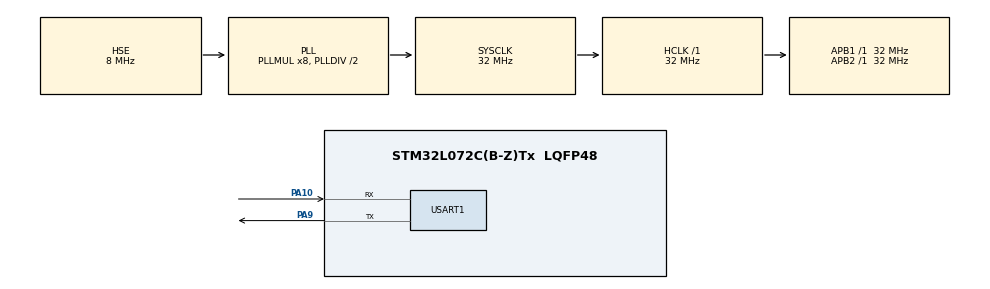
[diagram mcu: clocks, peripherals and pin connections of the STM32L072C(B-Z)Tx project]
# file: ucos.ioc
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Mcu.Family=STM32L0
Mcu.Name=STM32L072C(B-Z)Tx
Mcu.Package=LQFP48
PA10.Mode=Asynchronous
PA10.Signal=USART1_RX
PA13.Mode=Serial_Wire
PA13.Signal=SYS_SWDIO
PA14.Mode=Serial_Wire
PA14.Signal=SYS_SWCLK
PA9.Mode=Asynchronous
PA9.Signal=USART1_TX
PH0-OSC_IN.Mode=HSE-External-Oscillator
PH0-OSC_IN.Signal=RCC_OSC_IN
PH1-OSC_OUT.Mode=HSE-External-Oscillator
PH1-OSC_OUT.Signal=RCC_OSC_OUT
ProjectManager.HeapSize=0x200
ProjectManager.StackSize=0x400
ProjectManager.TargetToolchain=MDK-ARM V5
RCC.AHBFreq_Value=32000000
RCC.APB1Freq_Value=32000000
RCC.APB1TimFreq_Value=32000000
RCC.APB2Freq_Value=32000000
RCC.APB2TimFreq_Value=32000000
RCC.HCLKFreq_Value=32000000
RCC.HSE_VALUE=8000000
RCC.HSI16_VALUE=16000000
RCC.HSI48_VALUE=48000000
RCC.HSI_VALUE=16000000
RCC.LSE_VALUE=32768
RCC.MSI_VALUE=2097000
RCC.PLLMUL=RCC_PLLMUL_8
RCC.PLLSourceVirtual=RCC_PLLSOURCE_HSE
RCC.SYSCLKFreq_VALUE=32000000
RCC.SYSCLKSource=RCC_SYSCLKSOURCE_PLLCLK
RCC.VCOOutputFreq_Value=64000000
USART1.VirtualMode-Asynchronous=VM_ASYNC
USART1.WordLength=WORDLENGTH_8B
board=ucos

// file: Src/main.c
/**
  ******************************************************************************
  * File Name          : main.c
  * Description        : Main program body
  ******************************************************************************
  ** This notice applies to any and all portions of this file
  * that are not between comment pairs USER CODE BEGIN and
  * USER CODE END. Other portions of this file, whether
  * inserted by the user or by software development tools
  * are owned by their respective copyright owners.
  *
  * COPYRIGHT(c) 2018 STMicroelectronics
  *
  * Redistribution and use in source and binary forms, with or without modification,
  * are permitted provided that the following conditions are met:
  *   1. Redistributions of source code must retain the above copyright notice,
  *      this list of conditions and the following disclaimer.
  *   2. Redistributions in binary form must reproduce the above copyright notice,
  *      this list of conditions and the following disclaimer in the documentation
  *      and/or other materials provided with the distribution.
  *   3. Neither the name of STMicroelectronics nor the names of its contributors
  *      may be used to endorse or promote products derived from this software
  *      without specific prior written permission.
  *
  * THIS SOFTWARE IS PROVIDED BY THE COPYRIGHT HOLDERS AND CONTRIBUTORS "AS IS"
  * AND ANY EXPRESS OR IMPLIED WARRANTIES, INCLUDING, BUT NOT LIMITED TO, THE
  * IMPLIED WARRANTIES OF MERCHANTABILITY AND FITNESS FOR A PARTICULAR PURPOSE ARE
  * DISCLAIMED. IN NO EVENT SHALL THE COPYRIGHT HOLDER OR CONTRIBUTORS BE LIABLE
  * FOR ANY DIRECT, INDIRECT, INCIDENTAL, SPECIAL, EXEMPLARY, OR CONSEQUENTIAL
  * DAMAGES (INCLUDING, BUT NOT LIMITED TO, PROCUREMENT OF SUBSTITUTE GOODS OR
  * SERVICES; LOSS OF USE, DATA, OR PROFITS; OR BUSINESS INTERRUPTION) HOWEVER
  * CAUSED AND ON ANY THEORY OF LIABILITY, WHETHER IN CONTRACT, STRICT LIABILITY,
  * OR TORT (INCLUDING NEGLIGENCE OR OTHERWISE) ARISING IN ANY WAY OUT OF THE USE
  * OF THIS SOFTWARE, EVEN IF ADVISED OF THE POSSIBILITY OF SUCH DAMAGE.
  *
  ******************************************************************************
  */

#include "main.h"
#include "stm32l0xx_hal.h"
#include "usart.h"
#include "gpio.h"

/* USER CODE BEGIN Includes */

#include "os.h"

/* USER CODE END Includes */

/* USER CODE BEGIN PV */
/* Private variables ---------------------------------------------------------*/

/* USER CODE END PV */

void SystemClock_Config(void);

/* USER CODE BEGIN PFP */
/* Private function prototypes -----------------------------------------------*/

/* USER CODE END PFP */

/* USER CODE BEGIN 0 */

static  OS_TCB          AppTaskStartTCB;

static  CPU_STK         AppTaskStartStk[APP_CFG_TASK_START_STK_SIZE];

        OS_TMR          AppLED3Tmr;
        OS_SEM          AppLED3Sem;

        OS_TMR          AppLED4Tmr;
        OS_Q            AppLED4MsgQ;

        CPU_INT08U      AppLEDNbr;

/*
*********************************************************************************************************
*                                         FUNCTION PROTOTYPES
*********************************************************************************************************
*/

static  void  AppTaskStart              (void        *p_arg);
                                                                /* Timer callback functions for LED applications        */
        void  AppLED3TmrCallBack        (OS_TMR *p_tmr,
                                         void   *p_arg);

        void  AppLED4TmrCallBack        (OS_TMR *p_tmr,
                                         void   *p_arg);

/* USER CODE END 0 */

int main(void)
{

  /* USER CODE BEGIN 1 */

	OS_ERR      err;
#if (CPU_CFG_NAME_ERR == DEF_ENABLED)
    CPU_ERR     cpu_err;
#endif

  /* USER CODE END 1 */

  /* MCU Configuration----------------------------------------------------------*/

  /* Reset of all peripherals, Initializes the Flash interface and the Systick. */
  HAL_Init();

  /* Configure the system clock */
  SystemClock_Config();

  /* Initialize all configured peripherals */
  MX_GPIO_Init();
  MX_USART1_UART_Init();

  /* USER CODE BEGIN 2 */

	  CPU_Init();

    OSInit(&err);                                               /* Initialize "uC/OS-II, The Real-Time Kernel"          */

    OSTaskCreate((OS_TCB      *)&AppTaskStartTCB,               /* Create the start task                                */
                 (CPU_CHAR    *)"App Task Start",
                 (OS_TASK_PTR  )AppTaskStart,
                 (void        *)0,
                 (OS_PRIO      )APP_CFG_TASK_START_PRIO,
                 (CPU_STK     *)&AppTaskStartStk[0],
                 (CPU_STK_SIZE )APP_CFG_TASK_START_STK_SIZE_LIMIT,
                 (CPU_STK_SIZE )APP_CFG_TASK_START_STK_SIZE,
                 (OS_MSG_QTY   )0,
                 (OS_TICK      )0,
                 (void        *)0,
                 (OS_OPT       )(OS_OPT_TASK_STK_CHK | OS_OPT_TASK_STK_CLR),
                 (OS_ERR      *)&err);

    OSStart(&err);                                              /* Start multitasking (i.e. give control to uC/OS-II)   */

    return (1);
}

/** System Clock Configuration
*/
void SystemClock_Config(void)
{

  RCC_OscInitTypeDef RCC_OscInitStruct;
  RCC_ClkInitTypeDef RCC_ClkInitStruct;
  RCC_PeriphCLKInitTypeDef PeriphClkInit;

    /**Configure the main internal regulator output voltage
    */
  __HAL_PWR_VOLTAGESCALING_CONFIG(PWR_REGULATOR_VOLTAGE_SCALE1);

    /**Initializes the CPU, AHB and APB busses clocks
    */
  RCC_OscInitStruct.OscillatorType = RCC_OSCILLATORTYPE_HSE;
  RCC_OscInitStruct.HSEState = RCC_HSE_ON;
  RCC_OscInitStruct.PLL.PLLState = RCC_PLL_ON;
  RCC_OscInitStruct.PLL.PLLSource = RCC_PLLSOURCE_HSE;
  RCC_OscInitStruct.PLL.PLLMUL = RCC_PLLMUL_8;
  RCC_OscInitStruct.PLL.PLLDIV = RCC_PLLDIV_2;
  if (HAL_RCC_OscConfig(&RCC_OscInitStruct) != HAL_OK)
  {
    _Error_Handler(__FILE__, __LINE__);
  }

    /**Initializes the CPU, AHB and APB busses clocks
    */
  RCC_ClkInitStruct.ClockType = RCC_CLOCKTYPE_HCLK|RCC_CLOCKTYPE_SYSCLK
                              |RCC_CLOCKTYPE_PCLK1|RCC_CLOCKTYPE_PCLK2;
  RCC_ClkInitStruct.SYSCLKSource = RCC_SYSCLKSOURCE_PLLCLK;
  RCC_ClkInitStruct.AHBCLKDivider = RCC_SYSCLK_DIV1;
  RCC_ClkInitStruct.APB1CLKDivider = RCC_HCLK_DIV1;
  RCC_ClkInitStruct.APB2CLKDivider = RCC_HCLK_DIV1;

  if (HAL_RCC_ClockConfig(&RCC_ClkInitStruct, FLASH_LATENCY_1) != HAL_OK)
  {
    _Error_Handler(__FILE__, __LINE__);
  }

  PeriphClkInit.PeriphClockSelection = RCC_PERIPHCLK_USART1;
  PeriphClkInit.Usart1ClockSelection = RCC_USART1CLKSOURCE_PCLK2;
  if (HAL_RCCEx_PeriphCLKConfig(&PeriphClkInit) != HAL_OK)
  {
    _Error_Handler(__FILE__, __LINE__);
  }

    /**Configure the Systick interrupt time
    */
  HAL_SYSTICK_Config(HAL_RCC_GetHCLKFreq()/1000);

    /**Configure the Systick
    */
  HAL_SYSTICK_CLKSourceConfig(SYSTICK_CLKSOURCE_HCLK);

  /* SysTick_IRQn interrupt configuration */
  HAL_NVIC_SetPriority(SysTick_IRQn, 0, 0);
}

/* USER CODE BEGIN 4 */

/*
*********************************************************************************************************
*                                          STARTUP TASK
*
* Description : This is an example of a startup task.  As mentioned in the book's text, you MUST
*               initialize the ticker only once multitasking has started.
*
* Arguments   : p_arg   is the argument passed to 'AppTaskStart()' by 'OSTaskCreate()'.
*
* Returns     : none
*
* Notes       : 1) The first line of code is used to prevent a compiler warning because 'p_arg' is not
*                  used.  The compiler should not generate any code for this statement.
*********************************************************************************************************
*/

static  void  AppTaskStart (void *p_arg)
{
    CPU_INT32U  cpu_clk_freq;
    CPU_INT32U  cnts;

    OS_ERR      os_err;

    (void)p_arg;                                                /* Note #1                                             */

    cpu_clk_freq = BSP_CPU_ClkFreq();                           /* Determine SysTick reference freq.                    */
    cnts         = cpu_clk_freq                                 /* Determine nbr SysTick increments                     */
                 / (CPU_INT32U)OSCfg_TickRate_Hz;

    OS_CPU_SysTickInit(cnts);                                   /* Init uC/OS periodic time src (SysTick).              */

#if OS_CFG_STAT_TASK_EN > 0u
    OSStatTaskCPUUsageInit(&os_err);                            /* Compute CPU capacity with no task running            */
#endif

    while (DEF_TRUE) {                                          /* Task body, always written as an infinite loop.       */

        printf("helloworld\r\n");
				printf("haha\r\n");
				printf("welcome\r\n");

        OSTimeDlyHMSM(0, 0, 1, 0,
                      OS_OPT_TIME_HMSM_STRICT,
                      &os_err);
    }
}

/* USER CODE END 4 */

void _Error_Handler(char * file, int line)
{
  while(1)
  {
  }
}

/************************ (C) COPYRIGHT STMicroelectronics *****END OF FILE****/
